# netx90_app register map
File version: 1.0
CPU: CM4 r0p1, little endian, MPU, FPU, 4 interrupt priority bits, 78 interrupts
Registers are 32-bit, read-write, reset 0x0 unless marked. A register's access mark holds for its fields unless they carry their own. Offsets are from the block's base; [hi:lo] are bit positions; {n}, {i} and the like mark numbered series; 'fields as' and 'values as' point back to an identical list.

## module_firewall_ctrl
Base 0xFF401740
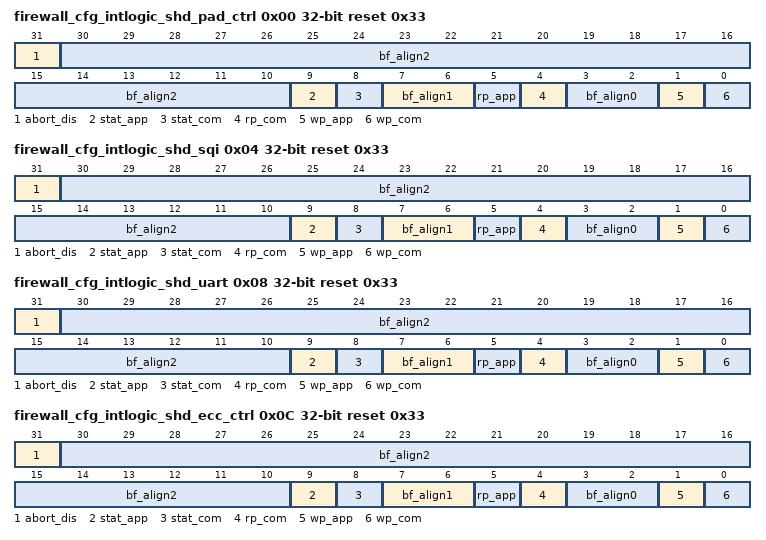
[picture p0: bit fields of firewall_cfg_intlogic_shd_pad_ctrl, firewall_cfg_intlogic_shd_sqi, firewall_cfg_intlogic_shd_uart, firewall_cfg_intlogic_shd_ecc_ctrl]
0x00 firewall_cfg_intlogic_shd_pad_ctrl reset 0x33 (reset mask 0x80000333) — Firewall configuration register for the intlogic_shd_pad_ctrl module. Basic function: A denied access will generate an ERROR-response (abort). Masters which cannot handle aborts directly can generate an IRQ to their controlling master when they receive an abort (e.g. the DPM-master can generate an IRQ to its host or the DMA-controllers can generate an IRQ to the ARM-CPU). The firewall will no generate any IRQ by itself. A denied write access will be junked. A denied read access will return unpredictable data. Note: COM-side masters are: DPM0, DPM1, XC01, XPIC_COM, ARM_COM, DMAC_COM. APP-side masters are: IDPM_MASTER, XPIC_APP, ARM_APP, DMAC_APP. Other masters which cannot be filtered but globally disabled are: ADC_MASTER, IPC_MASTER, DEBUG_MASTER. Note: The configuration bits of this register can be locked to protect it from reconfiguration by ASIC_CTRL_COM.netx_lock.lock_firewall. The functionality of the status bits are not influenced by ASIC_CTRL_COM.netx_lock.lock_firewall.
  [31] abort_dis — disable abort-generation for denied accesses 1: no ERROR response for denied accesses (not recommended). 0: ERROR response for denied accesses (default)
  [30:10] bf_align2 — bitField alignment value for aeabi compatibility
  [9] stat_app — status for APP side masters, write '1' to clear.
  [8] stat_com — Firewall status for COM side masters, write '1' to clear. 1: an access of the COM side was denied 0: no denied accesses Note: Clearing the stat-bit by software has lower priority than setting by hardware. I.e. clearing a status bit while an access of the related is denied, will fail. Ensure that no access will be denied before clearing by stopping accessing master (e.g. DMAC which could perform long jobs with long bursts).
  [7:6] bf_align1 — bitField alignment value for aeabi compatibility
  [5] rp_app — read permission for APP side masters
  [4] rp_com — read permission for COM side masters 1: permit read access 0: deny read access
  [3:2] bf_align0 — bitField alignment value for aeabi compatibility
  [1] wp_app — write permission for APP side masters
  [0] wp_com — write permission for COM side masters 1: permit write access 0: deny write access
0x04 firewall_cfg_intlogic_shd_sqi reset 0x33 (reset mask 0x80000333) — Firewall configuration register for the intlogic_shd_sqi module. See description of register firewall_cfg_intlogic_shd_pad_ctrl for details. Note: The configuration bits of this register can be locked to protect it from reconfiguration by ASIC_CTRL_COM.netx_lock.lock_firewall. The functionality of the status bits are not influenced by ASIC_CTRL_COM.netx_lock.lock_firewall.
  [31] abort_dis — disable abort-generation for denied accesses
  [30:10] bf_align2 — bitField alignment value for aeabi compatibility
  [9] stat_app — status for APP side masters, write '1' to clear.
  [8] stat_com — Firewall status for COM side masters, write '1' to clear.
  [7:6] bf_align1 — bitField alignment value for aeabi compatibility
  [5] rp_app — read permission for APP side masters
  [4] rp_com — read permission for COM side masters
  [3:2] bf_align0 — bitField alignment value for aeabi compatibility
  [1] wp_app — write permission for APP side masters
  [0] wp_com — write permission for COM side masters
0x08 firewall_cfg_intlogic_shd_uart reset 0x33 (reset mask 0x80000333) — Firewall configuration register for the intlogic_shd_uart module. See description of register firewall_cfg_intlogic_shd_pad_ctrl for details. Note: The configuration bits of this register can be locked to protect it from reconfiguration by ASIC_CTRL_COM.netx_lock.lock_firewall. The functionality of the status bits are not influenced by ASIC_CTRL_COM.netx_lock.lock_firewall.
  fields as firewall_cfg_intlogic_shd_sqi
0x0C firewall_cfg_intlogic_shd_ecc_ctrl reset 0x33 (reset mask 0x80000333) — Firewall configuration register for the intlogic_shd_ecc_ctrl module. See description of register firewall_cfg_intlogic_shd_pad_ctrl for details. Note: The configuration bits of this register can be locked to protect it from reconfiguration by ASIC_CTRL_COM.netx_lock.lock_firewall. The functionality of the status bits are not influenced by ASIC_CTRL_COM.netx_lock.lock_firewall.
  fields as firewall_cfg_intlogic_shd_sqi
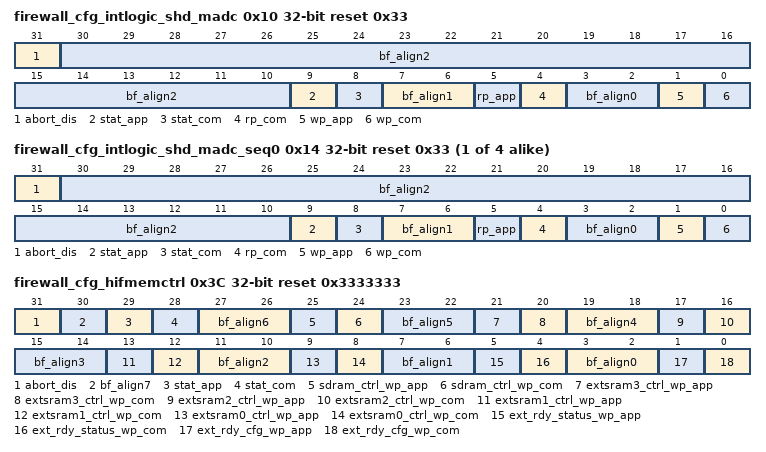
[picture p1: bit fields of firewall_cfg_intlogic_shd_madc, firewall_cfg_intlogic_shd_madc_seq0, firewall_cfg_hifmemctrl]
0x10 firewall_cfg_intlogic_shd_madc reset 0x33 (reset mask 0x80000333) — Firewall configuration register for the intlogic_shd_madc module. See description of register firewall_cfg_intlogic_shd_pad_ctrl for details. Note: The configuration bits of this register can be locked to protect it from reconfiguration by ASIC_CTRL_COM.netx_lock.lock_firewall. The functionality of the status bits are not influenced by ASIC_CTRL_COM.netx_lock.lock_firewall.
  fields as firewall_cfg_intlogic_shd_sqi
{0x14+4i} firewall_cfg_intlogic_shd_madc_seq{i} reset 0x33 (reset mask 0x80000333) (i=0..3) — Firewall configuration register for the intlogic_shd_madc_seq{i} module. See description of register firewall_cfg_intlogic_shd_pad_ctrl for details. Note: The configuration bits of this register can be locked to protect it from reconfiguration by ASIC_CTRL_COM.netx_lock.lock_firewall. The functionality of the status bits are not influenced by ASIC_CTRL_COM.netx_lock.lock_firewall.
  fields as firewall_cfg_intlogic_shd_sqi
0x3C firewall_cfg_hifmemctrl reset 0x3333333 (reset mask 0xB3333333) — Firewall configuration register for the configuration registers of the HIF MI. See description of register firewall_cfg_intlogic_shd_pad_ctrl for details. Note that read access cannot be blocked for the configuration registers of the HIF MI. The failed-access-status is not logged individually for each MI configuration register. Note: The configuration bits of this register can be locked to protect it from reconfiguration by ASIC_CTRL_COM.netx_lock.lock_firewall. The functionality of the status bits are not influenced by ASIC_CTRL_COM.netx_lock.lock_firewall.
  [31] abort_dis — Disable abort-generation for denied accesses for all registers controlled by this register.
  [30] bf_align7 — bitField alignment value for aeabi compatibility
  [29] stat_app — Status for APP side masters for all registers above, write '1' to clear.
  [28] stat_com — Firewall status for COM side masters for all registers above, write '1' to clear.
  [4n+3:4n+2] bf_align{n} (n=0..6) — bitField alignment value for aeabi compatibility
  [25] sdram_ctrl_wp_app — Write permission for APP side masters for the following register(s): all registers of hif_sdram_ctrl and hifmem_priority_ctrl
  [24] sdram_ctrl_wp_com — Write permission for COM side masters for the following register(s): all registers of hif_sdram_ctrl and hifmem_priority_ctrl
  [21] extsram3_ctrl_wp_app — Write permission for APP side masters for the following register(s): hif_asyncmem_ctrl.extsram3_ctrl
  [20] extsram3_ctrl_wp_com — Write permission for COM side masters for the following register(s): hif_asyncmem_ctrl.extsram3_ctrl
  [17] extsram2_ctrl_wp_app — Write permission for APP side masters for the following register(s): hif_asyncmem_ctrl.extsram2_ctrl
  [16] extsram2_ctrl_wp_com — Write permission for COM side masters for the following register(s): hif_asyncmem_ctrl.extsram2_ctrl
  [13] extsram1_ctrl_wp_app — Write permission for APP side masters for the following register(s): hif_asyncmem_ctrl.extsram1_ctrl
  [12] extsram1_ctrl_wp_com — Write permission for COM side masters for the following register(s): hif_asyncmem_ctrl.extsram1_ctrl
  [9] extsram0_ctrl_wp_app — Write permission for APP side masters for the following register(s): hif_asyncmem_ctrl.extsram0_ctrl and hif_asyncmem_ctrl.ext_cs0_apm_ctr
  [8] extsram0_ctrl_wp_com — Write permission for COM side masters for the following register(s): hif_asyncmem_ctrl.extsram0_ctrl and hif_asyncmem_ctrl.ext_cs0_apm_ctr
  [5] ext_rdy_status_wp_app — Write permission for APP side masters for the following register(s): hif_asyncmem_ctrl.ext_rdy_status
  [4] ext_rdy_status_wp_com — Write permission for COM side masters for the following register(s): hif_asyncmem_ctrl.ext_rdy_status
  [1] ext_rdy_cfg_wp_app — Write permission for APP side masters for the following register(s): hif_asyncmem_ctrl.ext_rdy_cfg
  [0] ext_rdy_cfg_wp_com — Write permission for COM side masters for the following register(s): hif_asyncmem_ctrl.ext_rdy_cfg
